# TM4C1294NCPDT register map
Vendor: Texas Instruments; File version: 2.2.0.295
CPU: CM4 r0p1, little endian, MPU, FPU, 3 interrupt priority bits
Registers are 32-bit, read-write, no defined reset value unless marked. A register's access mark holds for its fields unless they carry their own. Offsets are from the block's base; [hi:lo] are bit positions; {n}, {i} and the like mark numbered series; 'fields as' and 'values as' point back to an identical list.

## PWM0 — PWM (PWM0)
Base 0x40028000
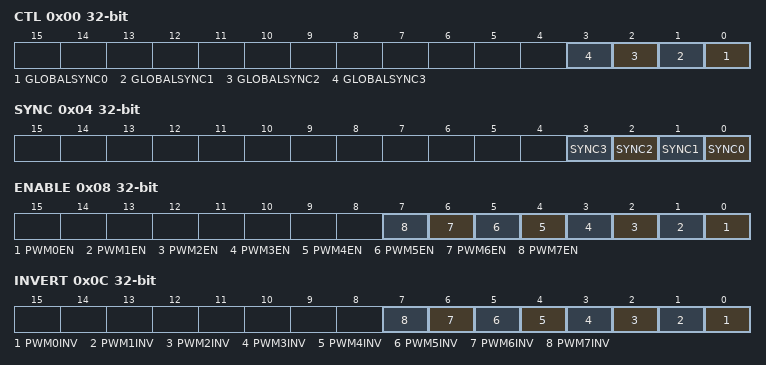
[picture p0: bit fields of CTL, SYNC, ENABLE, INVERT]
0x00 CTL
  [n] GLOBALSYNC{n} (n=0..3) — Update PWM Generator {n}
0x04 SYNC
  [n] SYNC{n} (n=0..3) — Reset Generator {n} Counter
0x08 ENABLE
  [n] PWM{n}EN (n=0..7) — MnPWM{n} Output Enable
0x0C INVERT
  [n] PWM{n}INV (n=0..7) — Invert MnPWM{n} Signal
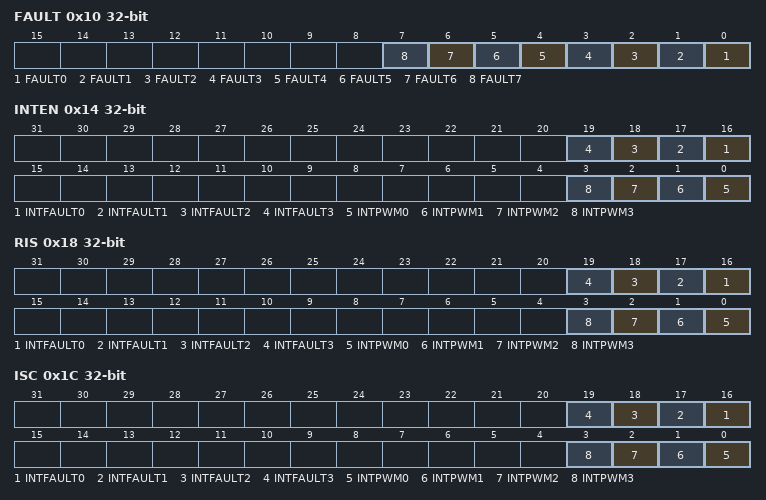
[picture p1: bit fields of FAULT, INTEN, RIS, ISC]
0x10 FAULT
  [n] FAULT{n} (n=0..7) — MnPWM{n} Fault
0x14 INTEN
  [n+16] INTFAULT{n} (n=0..3) — Interrupt Fault {n}
  [n] INTPWM{n} (n=0..3) — PWM{n} Interrupt Enable
0x18 RIS
  [n+16] INTFAULT{n} (n=0..3) — Interrupt Fault PWM {n}
  [n] INTPWM{n} (n=0..3) — PWM{n} Interrupt Asserted
0x1C ISC
  [n+16] INTFAULT{n} (n=0..3) — FAULT{n} Interrupt Asserted
  [n] INTPWM{n} (n=0..3) — PWM{n} Interrupt Status
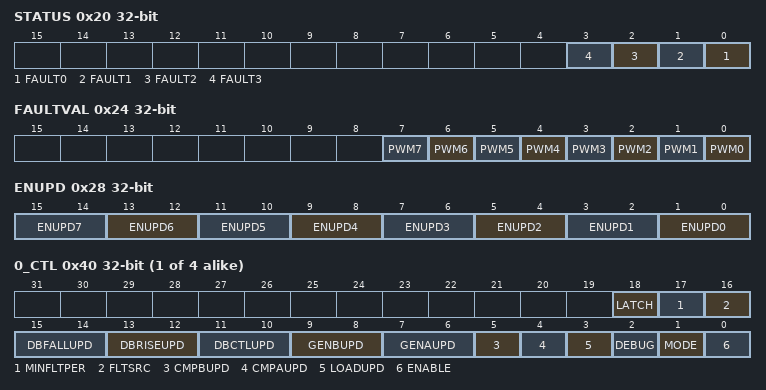
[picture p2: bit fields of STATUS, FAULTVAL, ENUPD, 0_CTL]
0x20 STATUS
  [n] FAULT{n} (n=0..3) — Generator {n} Fault Status
0x24 FAULTVAL
  [n] PWM{n} (n=0..7) — MnPWM{n} Fault Value
0x28 ENUPD
  [all] fields
    0=IMM (Immediate); 2=LSYNC (Locally Synchronized); 3=GSYNC (Globally Synchronized)
  [2n+1:2n] ENUPD{n} (n=0..7) — MnPWM{n} Enable Update Mode
{0x40+0x40*i} {i}_CTL (i=0..3)
  [18] LATCH — Latch Fault Input
  [17] MINFLTPER — Minimum Fault Period
  [16] FLTSRC — Fault Condition Source
  [15:14] DBFALLUPD — PWMnDBFALL Update Mode
    0=I (Immediate); 2=LS (Locally Synchronized); 3=GS (Globally Synchronized)
  [13:12] DBRISEUPD — PWMnDBRISE Update Mode
    values as DBFALLUPD
  [11:10] DBCTLUPD — PWMnDBCTL Update Mode
    values as DBFALLUPD
  [9:8] GENBUPD — PWMnGENB Update Mode
    values as DBFALLUPD
  [7:6] GENAUPD — PWMnGENA Update Mode
    values as DBFALLUPD
  [5] CMPBUPD — Comparator B Update Mode
  [4] CMPAUPD — Comparator A Update Mode
  [3] LOADUPD — Load Register Update Mode
  [2] DEBUG — Debug Mode
  [1] MODE — Counter Mode
  [0] ENABLE — PWM Block Enable
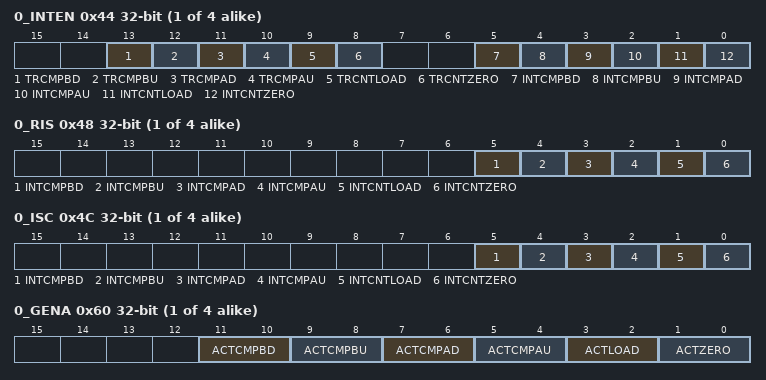
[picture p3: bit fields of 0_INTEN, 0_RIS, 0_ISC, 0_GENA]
{0x44+0x40*i} {i}_INTEN (i=0..3)
  [13] TRCMPBD — Trigger for Counter=PWMnCMPB
  [12] TRCMPBU — Trigger for Counter=PWMnCMPB Up
  [11] TRCMPAD — Trigger for Counter=PWMnCMPA
  [10] TRCMPAU — Trigger for Counter=PWMnCMPA Up
  [9] TRCNTLOAD — Trigger for Counter=PWMnLOAD
  [8] TRCNTZERO — Trigger for Counter=0
  [5] INTCMPBD — Interrupt for Counter=PWMnCMPB
  [4] INTCMPBU — Interrupt for Counter=PWMnCMPB
  [3] INTCMPAD — Interrupt for Counter=PWMnCMPA
  [2] INTCMPAU — Interrupt for Counter=PWMnCMPA
  [1] INTCNTLOAD — Interrupt for Counter=PWMnLOAD
  [0] INTCNTZERO — Interrupt for Counter=0
{0x48+0x40*i} {i}_RIS (i=0..3)
  [5] INTCMPBD — Comparator B Down Interrupt
  [4] INTCMPBU — Comparator B Up Interrupt Status
  [3] INTCMPAD — Comparator A Down Interrupt
  [2] INTCMPAU — Comparator A Up Interrupt Status
  [1] INTCNTLOAD — Counter=Load Interrupt Status
  [0] INTCNTZERO — Counter=0 Interrupt Status
{0x4C+0x40*i} {i}_ISC (i=0..3)
  [5] INTCMPBD — Comparator B Down Interrupt
  [4] INTCMPBU — Comparator B Up Interrupt
  [3] INTCMPAD — Comparator A Down Interrupt
  [2] INTCMPAU — Comparator A Up Interrupt
  [1] INTCNTLOAD — Counter=Load Interrupt
  [0] INTCNTZERO — Counter=0 Interrupt
0x50 0_LOAD
  [15:0] VALUE — Counter Load Value
0x54 0_COUNT
  [15:0] VALUE — Counter Value
0x58 0_CMPA
  [15:0] VALUE — Comparator A Value
0x5C 0_CMPB
  [15:0] VALUE — Comparator B Value
{0x60+0x40*i} {i}_GENA (i=0..3)
  [all] fields
    0=NONE (Do nothing); 1=INV (Invert pwmA); 2=ZERO (Drive pwmA Low); 3=ONE (Drive pwmA High)
  [11:10] ACTCMPBD — Action for Comparator B Down
  [9:8] ACTCMPBU — Action for Comparator B Up
  [7:6] ACTCMPAD — Action for Comparator A Down
  [5:4] ACTCMPAU — Action for Comparator A Up
  [3:2] ACTLOAD — Action for Counter=LOAD
  [1:0] ACTZERO — Action for Counter=0
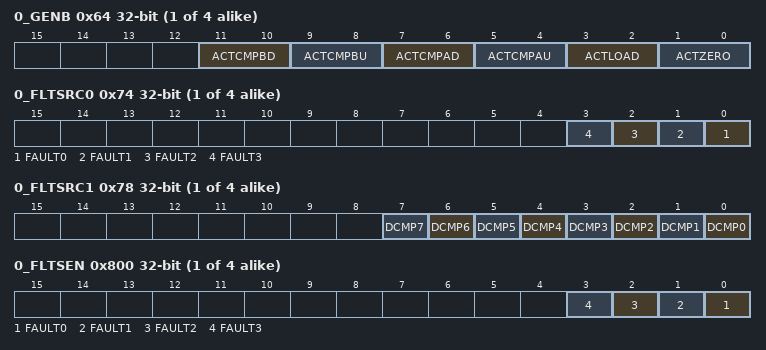
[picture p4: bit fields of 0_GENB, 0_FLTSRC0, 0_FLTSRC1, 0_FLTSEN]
{0x64+0x40*i} {i}_GENB (i=0..3)
  [all] fields
    0=NONE (Do nothing); 1=INV (Invert pwmB); 2=ZERO (Drive pwmB Low); 3=ONE (Drive pwmB High)
  [11:10] ACTCMPBD — Action for Comparator B Down
  [9:8] ACTCMPBU — Action for Comparator B Up
  [7:6] ACTCMPAD — Action for Comparator A Down
  [5:4] ACTCMPAU — Action for Comparator A Up
  [3:2] ACTLOAD — Action for Counter=LOAD
  [1:0] ACTZERO — Action for Counter=0
{0x68+0x40*i} {i}_DBCTL (i=0..3)
  [0] ENABLE — Dead-Band Generator Enable
0x6C 0_DBRISE
  [11:0] DELAY — Dead-Band Rise Delay
0x70 0_DBFALL
  [11:0] DELAY — Dead-Band Fall Delay
{0x74+0x40*i} {i}_FLTSRC0 (i=0..3)
  [n] FAULT{n} (n=0..3) — Fault{n} Input
{0x78+0x40*i} {i}_FLTSRC1 (i=0..3)
  [n] DCMP{n} (n=0..7) — Digital Comparator {n}
0x7C 0_MINFLTPER
  [15:0] VALUE — Minimum Fault Period
{0x50+0x40*i} {i}_LOAD (i=1..3)
  [15:0] LOAD — Counter Load Value
{0x54+0x40*i} {i}_COUNT (i=1..3)
  [15:0] COUNT — Counter Value
{0x58+0x40*i} {i}_CMPA (i=1..3)
  [15:0] COMPA — Comparator A Value
{0x5C+0x40*i} {i}_CMPB (i=1..3)
  [15:0] COMPB — Comparator B Value
{0x6C+0x40*i} {i}_DBRISE (i=1..3)
  [11:0] RISEDELAY — Dead-Band Rise Delay
{0x70+0x40*i} {i}_DBFALL (i=1..3)
  [11:0] FALLDELAY — Dead-Band Fall Delay
{0x7C+0x40*i} {i}_MINFLTPER (i=1..3)
  [15:0] MFP — Minimum Fault Period
{0x800+0x80*i} {i}_FLTSEN (i=0..3)
  [n] FAULT{n} (n=0..3) — Fault{n} Sense
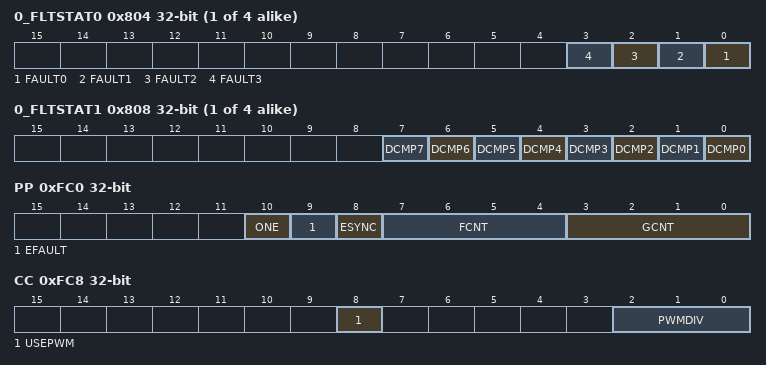
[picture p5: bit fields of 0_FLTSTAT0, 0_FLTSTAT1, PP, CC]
{0x804+0x80*i} {i}_FLTSTAT0 (i=0..3)
  [n] FAULT{n} (n=0..3) — Fault Input {n}
{0x808+0x80*i} {i}_FLTSTAT1 (i=0..3)
  [n] DCMP{n} (n=0..7) — Digital Comparator {n} Trigger
0xFC0 PP
  [10] ONE — One-Shot Mode
  [9] EFAULT — Extended Fault
  [8] ESYNC — Extended Synchronization
  [7:4] FCNT — Fault Inputs (per PWM unit)
  [3:0] GCNT — Generators
0xFC8 CC
  [8] USEPWM — Use PWM Clock Divisor
  [2:0] PWMDIV — PWM Clock Divider
    0=2; 1=4; 2=8; 3=16; 4=32; 5=64
